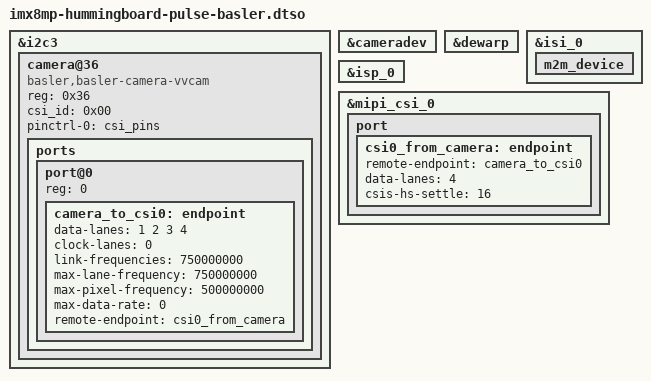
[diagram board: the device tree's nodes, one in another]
// SPDX-License-Identifier: (GPL-2.0+ OR MIT)
/*
 * Copyright 2025 Josua Mayer <josua@solid-run.com>
 *
 * Overlay for Basler camera attached to HummingBoard Pulse camera connector.
 */

/dts-v1/;
/plugin/;

&i2c3 {
	#address-cells = <1>;
	#size-cells = <0>;

	camera@36 {
		compatible = "basler,basler-camera-vvcam";
		reg = <0x36>;
		csi_id = <0x00>;
		pinctrl-0 = <&csi_pins>;
		pinctrl-names = "default";

		ports {
			#address-cells = <1>;
			#size-cells = <0>;

			port@0 {
				reg = <0>;

				camera_to_csi0: endpoint {
					data-lanes = <1 2 3 4>;
					clock-lanes = <0>;
					link-frequencies = /bits/ 64 <750000000>;
					max-lane-frequency = /bits/ 64 <750000000>;
					max-pixel-frequency = /bits/ 64 <500000000>;
					max-data-rate = /bits/ 64 <0>;
					remote-endpoint = <&csi0_from_camera>;
				};
			};
		};
	};
};

&cameradev {
	status = "okay";
};

&dewarp {
	status = "okay";
};

&isi_0 {
	status = "okay";

	m2m_device {
		status = "okay";
	};
};

&isp_0 {
	status = "okay";
};

&mipi_csi_0 {
	status = "okay";

	/*
	 * imx8-media-dev driver expects ports as direct sub-nodes,
	 * rather than below a parts node.
	 * Compare camera definition above for new style.
	 */
	port {
		csi0_from_camera: endpoint {
			remote-endpoint = <&camera_to_csi0>;
			data-lanes = <4>;
			csis-hs-settle = <16>;
		};
	};
};
